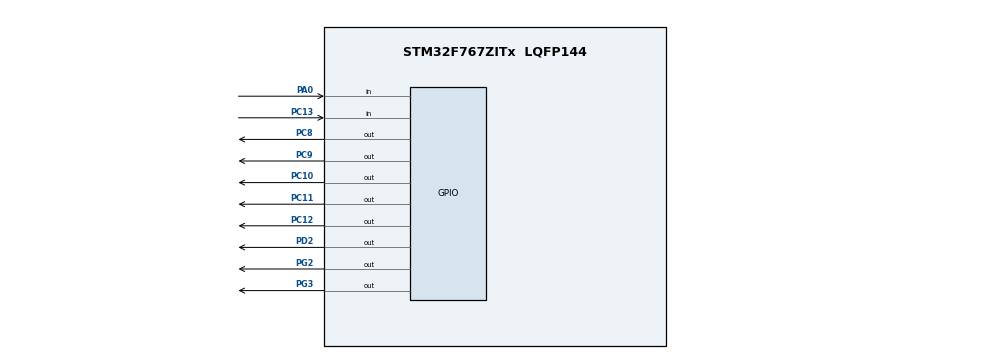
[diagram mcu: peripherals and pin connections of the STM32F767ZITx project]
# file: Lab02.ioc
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Mcu.Family=STM32F7
Mcu.Name=STM32F767ZITx
Mcu.Package=LQFP144
NVIC.PriorityGroup=NVIC_PRIORITYGROUP_4
PA0/WKUP.Signal=GPIO_Input
PC10.Signal=GPIO_Output
PC11.Signal=GPIO_Output
PC12.Signal=GPIO_Output
PC13.Signal=GPIO_Input
PC8.Signal=GPIO_Output
PC9.Signal=GPIO_Output
PD2.Signal=GPIO_Output
PG2.Signal=GPIO_Output
PG3.Signal=GPIO_Output
ProjectManager.HeapSize=0x200
ProjectManager.StackSize=0x400
ProjectManager.TargetToolchain=STM32CubeIDE
RCC.HSE_VALUE=25000000
RCC.HSI_VALUE=16000000
RCC.LSE_VALUE=32768
RCC.USBFreq_Value=96000000
RCC.VCOOutputFreq_Value=192000000
board=custom

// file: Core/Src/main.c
/* USER CODE BEGIN Header */
/**
 ******************************************************************************
 * @file           : main.c
 * @brief          : Main program body
 ******************************************************************************
 * @attention
 *
 * Copyright (c) 2023 STMicroelectronics.
 * All rights reserved.
 *
 * This software is licensed under terms that can be found in the LICENSE file
 * in the root directory of this software component.
 * If no LICENSE file comes with this software, it is provided AS-IS.
 *
 ******************************************************************************
 */
/* USER CODE END Header */
#include "main.h"

/* USER CODE BEGIN PV */
uint8_t isEnd = 0;
uint16_t led1 = 0;
uint16_t temp = 0;
uint16_t temp2 = 0;
/* USER CODE END PV */

void SystemClock_Config(void);
static void MX_GPIO_Init(void);

int main(void) {

	/* MCU Configuration--------------------------------------------------------*/

	/* Reset of all peripherals, Initializes the Flash interface and the Systick. */
	HAL_Init();

	/* Configure the system clock */
	SystemClock_Config();

	/* Initialize all configured peripherals */
	MX_GPIO_Init();

	/* Infinite loop */
	while (1) {
		if (HAL_GPIO_ReadPin(GPIOA, GPIO_PIN_0) == GPIO_PIN_RESET) {
			if (led1 == 0) {
				HAL_GPIO_WritePin(GPIOG, GPIO_PIN_3, GPIO_PIN_SET);
				led1 = 8;
				HAL_Delay(500);
				HAL_GPIO_WritePin(GPIOG, GPIO_PIN_3, GPIO_PIN_RESET);
				HAL_Delay(500);

				HAL_GPIO_WritePin(GPIOG, GPIO_PIN_2, GPIO_PIN_SET);
				led1 = 7;
				HAL_Delay(500);
				HAL_GPIO_WritePin(GPIOG, GPIO_PIN_2, GPIO_PIN_RESET);
				HAL_Delay(500);

				HAL_GPIO_WritePin(GPIOD, GPIO_PIN_2, GPIO_PIN_SET);
				led1 = 6;
				HAL_Delay(500);
				HAL_GPIO_WritePin(GPIOD, GPIO_PIN_2, GPIO_PIN_RESET);
				HAL_Delay(500);

				HAL_GPIO_WritePin(GPIOC, GPIO_PIN_12, GPIO_PIN_SET);
				led1 = 5;
				HAL_Delay(500);
				HAL_GPIO_WritePin(GPIOC, GPIO_PIN_12, GPIO_PIN_RESET);
				HAL_Delay(500);

				HAL_GPIO_WritePin(GPIOC, GPIO_PIN_11, GPIO_PIN_SET);
				led1 = 4;
				HAL_Delay(500);
				HAL_GPIO_WritePin(GPIOC, GPIO_PIN_11, GPIO_PIN_RESET);
				HAL_Delay(500);

				HAL_GPIO_WritePin(GPIOC, GPIO_PIN_10, GPIO_PIN_SET);
				led1 = 3;
				HAL_Delay(500);
				HAL_GPIO_WritePin(GPIOC, GPIO_PIN_10, GPIO_PIN_RESET);
				HAL_Delay(500);

				HAL_GPIO_WritePin(GPIOC, GPIO_PIN_9, GPIO_PIN_SET);
				led1 = 2;
				HAL_Delay(500);
				HAL_GPIO_WritePin(GPIOC, GPIO_PIN_9, GPIO_PIN_RESET);
				HAL_Delay(500);

				HAL_GPIO_WritePin(GPIOC, GPIO_PIN_8, GPIO_PIN_SET);
				led1 = 1;
				HAL_Delay(500);
				HAL_GPIO_WritePin(GPIOC, GPIO_PIN_8, GPIO_PIN_RESET);
				HAL_Delay(500);

				led1 = 0;
			} else {

				temp = led1;
				temp2 = led1;
				do {

					if (led1 == 1) {
						HAL_GPIO_WritePin(GPIOC, GPIO_PIN_8, GPIO_PIN_RESET);
						HAL_Delay(500);
						HAL_GPIO_WritePin(GPIOG, GPIO_PIN_3, GPIO_PIN_SET);

						HAL_Delay(500);
						led1 = 8;
					} else if (led1 == 2) {

						HAL_GPIO_WritePin(GPIOC, GPIO_PIN_9, GPIO_PIN_RESET);

						HAL_Delay(500);
						HAL_GPIO_WritePin(GPIOC, GPIO_PIN_8, GPIO_PIN_SET);
						HAL_Delay(500);
						led1--;
					} else if (led1 == 3) {
						HAL_GPIO_WritePin(GPIOC, GPIO_PIN_10, GPIO_PIN_RESET);

						HAL_Delay(500);
						HAL_GPIO_WritePin(GPIOC, GPIO_PIN_9, GPIO_PIN_SET);
						HAL_Delay(500);
						led1--;

					} else if (led1 == 4) {
						HAL_GPIO_WritePin(GPIOC, GPIO_PIN_11, GPIO_PIN_RESET);

						HAL_Delay(500);
						HAL_GPIO_WritePin(GPIOC, GPIO_PIN_10, GPIO_PIN_SET);
						HAL_Delay(500);
						led1--;

					} else if (led1 == 5) {
						HAL_GPIO_WritePin(GPIOC, GPIO_PIN_12, GPIO_PIN_RESET);

						HAL_Delay(500);
						HAL_GPIO_WritePin(GPIOC, GPIO_PIN_11, GPIO_PIN_SET);
						HAL_Delay(500);
						led1--;

					} else if (led1 == 6) {
						HAL_GPIO_WritePin(GPIOD, GPIO_PIN_2, GPIO_PIN_RESET);

						HAL_Delay(500);
						HAL_GPIO_WritePin(GPIOC, GPIO_PIN_12, GPIO_PIN_SET);
						HAL_Delay(500);
						led1--;

					} else if (led1 == 7) {
						HAL_GPIO_WritePin(GPIOG, GPIO_PIN_2, GPIO_PIN_RESET);

						HAL_Delay(500);
						HAL_GPIO_WritePin(GPIOD, GPIO_PIN_2, GPIO_PIN_SET);
						HAL_Delay(500);
						led1--;

					} else if (led1 == 8) {
						HAL_GPIO_WritePin(GPIOG, GPIO_PIN_3, GPIO_PIN_RESET);

						HAL_Delay(500);
						HAL_GPIO_WritePin(GPIOG, GPIO_PIN_2, GPIO_PIN_SET);
						HAL_Delay(500);
						led1--;

					} else if (led1 == 0) {
						HAL_GPIO_WritePin(GPIOG, GPIO_PIN_3, GPIO_PIN_RESET);

						HAL_Delay(500);
						HAL_GPIO_WritePin(GPIOC, GPIO_PIN_8, GPIO_PIN_SET);
						HAL_Delay(500);
						led1--;

					}else {

					}

				} while ((led1 != temp));

			}

		} else if (HAL_GPIO_ReadPin(GPIOC, GPIO_PIN_13) == GPIO_PIN_SET) {
			if (led1 == 1) {
				HAL_GPIO_WritePin(GPIOC, GPIO_PIN_8, GPIO_PIN_RESET);
				HAL_GPIO_WritePin(GPIOC, GPIO_PIN_9, GPIO_PIN_SET);
				led1++;
				HAL_Delay(500);
			} else if (led1 == 2) {
				HAL_GPIO_WritePin(GPIOC, GPIO_PIN_9, GPIO_PIN_RESET);
				HAL_GPIO_WritePin(GPIOC, GPIO_PIN_10, GPIO_PIN_SET);
				led1++;
				HAL_Delay(500);
			} else if (led1 == 3) {
				HAL_GPIO_WritePin(GPIOC, GPIO_PIN_10, GPIO_PIN_RESET);
				HAL_GPIO_WritePin(GPIOC, GPIO_PIN_11, GPIO_PIN_SET);
				led1++;
				HAL_Delay(500);
			} else if (led1 == 4) {
				HAL_GPIO_WritePin(GPIOC, GPIO_PIN_11, GPIO_PIN_RESET);
				HAL_GPIO_WritePin(GPIOC, GPIO_PIN_12, GPIO_PIN_SET);
				led1++;
				HAL_Delay(500);
			} else if (led1 == 5) {
				HAL_GPIO_WritePin(GPIOC, GPIO_PIN_12, GPIO_PIN_RESET);
				HAL_GPIO_WritePin(GPIOD, GPIO_PIN_2, GPIO_PIN_SET);
				led1++;
				HAL_Delay(500);
			} else if (led1 == 6) {
				HAL_GPIO_WritePin(GPIOD, GPIO_PIN_2, GPIO_PIN_RESET);
				HAL_GPIO_WritePin(GPIOG, GPIO_PIN_2, GPIO_PIN_SET);
				led1++;
				HAL_Delay(500);
			} else if (led1 == 7) {
				HAL_GPIO_WritePin(GPIOG, GPIO_PIN_2, GPIO_PIN_RESET);
				HAL_GPIO_WritePin(GPIOG, GPIO_PIN_3, GPIO_PIN_SET);
				led1++;
				HAL_Delay(500);
			} else if (led1 == 8) {
				HAL_GPIO_WritePin(GPIOG, GPIO_PIN_3, GPIO_PIN_RESET);
				HAL_GPIO_WritePin(GPIOC, GPIO_PIN_8, GPIO_PIN_SET);
				led1 = 1;
				HAL_Delay(500);
			} else if (led1 == 0) {
				HAL_GPIO_WritePin(GPIOG, GPIO_PIN_3, GPIO_PIN_RESET);
				HAL_GPIO_WritePin(GPIOC, GPIO_PIN_8, GPIO_PIN_SET);
				led1++;
				HAL_Delay(500);
			} else {

			}
		}

	}
}

void SystemClock_Config(void) {
	RCC_OscInitTypeDef RCC_OscInitStruct = { 0 };
	RCC_ClkInitTypeDef RCC_ClkInitStruct = { 0 };

	/** Configure the main internal regulator output voltage
	 */
	__HAL_RCC_PWR_CLK_ENABLE();
	__HAL_PWR_VOLTAGESCALING_CONFIG(PWR_REGULATOR_VOLTAGE_SCALE3);

	/** Initializes the RCC Oscillators according to the specified parameters
	 * in the RCC_OscInitTypeDef structure.
	 */
	RCC_OscInitStruct.OscillatorType = RCC_OSCILLATORTYPE_HSI;
	RCC_OscInitStruct.HSIState = RCC_HSI_ON;
	RCC_OscInitStruct.HSICalibrationValue = RCC_HSICALIBRATION_DEFAULT;
	RCC_OscInitStruct.PLL.PLLState = RCC_PLL_NONE;
	if (HAL_RCC_OscConfig(&RCC_OscInitStruct) != HAL_OK) {
		Error_Handler();
	}

	/** Initializes the CPU, AHB and APB buses clocks
	 */
	RCC_ClkInitStruct.ClockType = RCC_CLOCKTYPE_HCLK | RCC_CLOCKTYPE_SYSCLK
			| RCC_CLOCKTYPE_PCLK1 | RCC_CLOCKTYPE_PCLK2;
	RCC_ClkInitStruct.SYSCLKSource = RCC_SYSCLKSOURCE_HSI;
	RCC_ClkInitStruct.AHBCLKDivider = RCC_SYSCLK_DIV1;
	RCC_ClkInitStruct.APB1CLKDivider = RCC_HCLK_DIV1;
	RCC_ClkInitStruct.APB2CLKDivider = RCC_HCLK_DIV1;

	if (HAL_RCC_ClockConfig(&RCC_ClkInitStruct, FLASH_LATENCY_0) != HAL_OK) {
		Error_Handler();
	}
}

static void MX_GPIO_Init(void) {
	GPIO_InitTypeDef GPIO_InitStruct = { 0 };

	/* GPIO Ports Clock Enable */
	__HAL_RCC_GPIOC_CLK_ENABLE();
	__HAL_RCC_GPIOA_CLK_ENABLE();
	__HAL_RCC_GPIOG_CLK_ENABLE();
	__HAL_RCC_GPIOD_CLK_ENABLE();

	/*Configure GPIO pin Output Level */
	HAL_GPIO_WritePin(GPIOG, GPIO_PIN_2 | GPIO_PIN_3, GPIO_PIN_RESET);

	/*Configure GPIO pin Output Level */
	HAL_GPIO_WritePin(GPIOC,
	GPIO_PIN_8 | GPIO_PIN_9 | GPIO_PIN_10 | GPIO_PIN_11 | GPIO_PIN_12,
			GPIO_PIN_RESET);

	/*Configure GPIO pin Output Level */
	HAL_GPIO_WritePin(GPIOD, GPIO_PIN_2, GPIO_PIN_RESET);

	/*Configure GPIO pin : PC13 */
	GPIO_InitStruct.Pin = GPIO_PIN_13;
	GPIO_InitStruct.Mode = GPIO_MODE_INPUT;
	GPIO_InitStruct.Pull = GPIO_NOPULL;
	HAL_GPIO_Init(GPIOC, &GPIO_InitStruct);

	/*Configure GPIO pin : PA0 */
	GPIO_InitStruct.Pin = GPIO_PIN_0;
	GPIO_InitStruct.Mode = GPIO_MODE_INPUT;
	GPIO_InitStruct.Pull = GPIO_NOPULL;
	HAL_GPIO_Init(GPIOA, &GPIO_InitStruct);

	/*Configure GPIO pins : PG2 PG3 */
	GPIO_InitStruct.Pin = GPIO_PIN_2 | GPIO_PIN_3;
	GPIO_InitStruct.Mode = GPIO_MODE_OUTPUT_PP;
	GPIO_InitStruct.Pull = GPIO_NOPULL;
	GPIO_InitStruct.Speed = GPIO_SPEED_FREQ_LOW;
	HAL_GPIO_Init(GPIOG, &GPIO_InitStruct);

	/*Configure GPIO pins : PC8 PC9 PC10 PC11
	 PC12 */
	GPIO_InitStruct.Pin = GPIO_PIN_8 | GPIO_PIN_9 | GPIO_PIN_10 | GPIO_PIN_11
			| GPIO_PIN_12;
	GPIO_InitStruct.Mode = GPIO_MODE_OUTPUT_PP;
	GPIO_InitStruct.Pull = GPIO_NOPULL;
	GPIO_InitStruct.Speed = GPIO_SPEED_FREQ_LOW;
	HAL_GPIO_Init(GPIOC, &GPIO_InitStruct);

	/*Configure GPIO pin : PD2 */
	GPIO_InitStruct.Pin = GPIO_PIN_2;
	GPIO_InitStruct.Mode = GPIO_MODE_OUTPUT_PP;
	GPIO_InitStruct.Pull = GPIO_NOPULL;
	GPIO_InitStruct.Speed = GPIO_SPEED_FREQ_LOW;
	HAL_GPIO_Init(GPIOD, &GPIO_InitStruct);

}

void Error_Handler(void) {
	__disable_irq();
	while (1) {
	}
}
